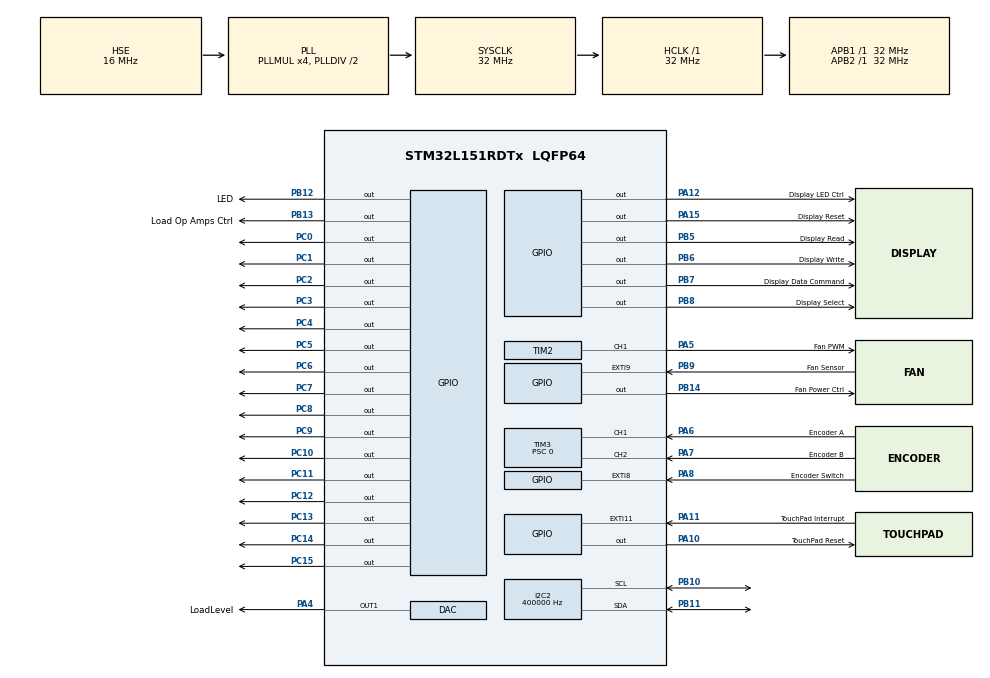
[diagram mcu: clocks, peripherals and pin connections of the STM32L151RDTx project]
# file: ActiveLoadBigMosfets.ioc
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DAC.DAC_OutputBuffer=DAC_OUTPUTBUFFER_DISABLE
I2C2.ClockSpeed=400000
I2C2.I2C_Mode=I2C_Fast
Mcu.Family=STM32L1
Mcu.Name=STM32L151RDTx
Mcu.Package=LQFP64
NVIC.EXTI15_10_IRQn=true\:0\:0\:false\:false\:true\:true\:true
NVIC.EXTI9_5_IRQn=true\:0\:0\:false\:false\:true\:true\:true
NVIC.PVD_IRQn=true\:0\:0\:false\:false\:true\:true\:true
NVIC.PriorityGroup=NVIC_PRIORITYGROUP_4
NVIC.TIM3_IRQn=true\:0\:0\:false\:false\:true\:true\:true
NVIC.TIM5_IRQn=true\:0\:0\:false\:false\:true\:true\:true
PA10.GPIO_Label=TouchPad Reset
PA10.PinState=GPIO_PIN_RESET
PA10.Signal=GPIO_Output
PA11.GPIO_Label=TouchPad Interrupt
PA11.GPIO_ModeDefaultEXTI=GPIO_MODE_IT_RISING_FALLING
PA11.GPIO_PuPd=GPIO_PULLDOWN
PA11.Signal=GPXTI11
PA12.GPIO_Label=Display LED Ctrl
PA12.GPIO_PuPd=GPIO_NOPULL
PA12.Signal=GPIO_Output
PA15.GPIO_Label=Display Reset
PA15.GPIO_Speed=GPIO_SPEED_FREQ_LOW
PA15.Signal=GPIO_Output
PA4.GPIO_Label=LoadLevel
PA4.Signal=COMP_DAC1_group
PA5.GPIO_Label=Fan PWM
PA5.GPIO_Speed=GPIO_SPEED_FREQ_VERY_HIGH
PA5.Signal=S_TIM2_CH1_ETR
PA6.GPIO_Label=Encoder A
PA6.GPIO_ModeDefaultPP=GPIO_MODE_AF_OD
PA6.GPIO_PuPd=GPIO_PULLUP
PA6.Signal=S_TIM3_CH1
PA7.GPIO_Label=Encoder B
PA7.GPIO_ModeDefaultPP=GPIO_MODE_AF_OD
PA7.GPIO_PuPd=GPIO_PULLUP
PA7.Signal=S_TIM3_CH2
PA8.GPIO_Label=Encoder Switch
PA8.GPIO_ModeDefaultEXTI=GPIO_MODE_IT_FALLING
PA8.GPIO_PuPd=GPIO_PULLUP
PA8.Signal=GPXTI8
PB10.Mode=I2C
PB10.Signal=I2C2_SCL
PB11.Mode=I2C
PB11.Signal=I2C2_SDA
PB12.GPIO_Label=LED
PB12.Signal=GPIO_Output
PB13.GPIO_Label=Load Op Amps Ctrl
PB13.Signal=GPIO_Output
PB14.GPIO_Label=Fan Power Ctrl
PB14.Signal=GPIO_Output
PB5.GPIO_Label=Display Read
PB5.Signal=GPIO_Output
PB6.GPIO_Label=Display Write
PB6.GPIO_Speed=GPIO_SPEED_FREQ_HIGH
PB6.Signal=GPIO_Output
PB7.GPIO_Label=Display Data Command
PB7.GPIO_Speed=GPIO_SPEED_FREQ_HIGH
PB7.Signal=GPIO_Output
PB8.GPIO_Label=Display Select
PB8.Signal=GPIO_Output
PB9.GPIO_Label=Fan Sensor
PB9.GPIO_ModeDefaultEXTI=GPIO_MODE_IT_FALLING
PB9.GPIO_PuPd=GPIO_PULLUP
PB9.Signal=GPXTI9
PC0.GPIO_Speed=GPIO_SPEED_FREQ_HIGH
PC0.Signal=GPIO_Output
PC1.GPIO_Speed=GPIO_SPEED_FREQ_HIGH
PC1.Signal=GPIO_Output
PC10.GPIO_Speed=GPIO_SPEED_FREQ_HIGH
PC10.Signal=GPIO_Output
PC11.GPIO_Speed=GPIO_SPEED_FREQ_HIGH
PC11.Signal=GPIO_Output
PC12.GPIO_Speed=GPIO_SPEED_FREQ_HIGH
PC12.Signal=GPIO_Output
PC13-WKUP2.GPIO_Speed=GPIO_SPEED_FREQ_HIGH
PC13-WKUP2.Signal=GPIO_Output
PC14-OSC32_IN.GPIO_Speed=GPIO_SPEED_FREQ_HIGH
PC14-OSC32_IN.Signal=GPIO_Output
PC15-OSC32_OUT.GPIO_Speed=GPIO_SPEED_FREQ_HIGH
PC15-OSC32_OUT.Signal=GPIO_Output
PC2.GPIO_Speed=GPIO_SPEED_FREQ_HIGH
PC2.Signal=GPIO_Output
PC3.GPIO_Speed=GPIO_SPEED_FREQ_HIGH
PC3.Signal=GPIO_Output
PC4.GPIO_Speed=GPIO_SPEED_FREQ_HIGH
PC4.Signal=GPIO_Output
PC5.GPIO_Speed=GPIO_SPEED_FREQ_HIGH
PC5.Signal=GPIO_Output
PC6.GPIO_Speed=GPIO_SPEED_FREQ_HIGH
PC6.Signal=GPIO_Output
PC7.GPIO_Speed=GPIO_SPEED_FREQ_HIGH
PC7.Signal=GPIO_Output
PC8.GPIO_Speed=GPIO_SPEED_FREQ_HIGH
PC8.Signal=GPIO_Output
PC9.GPIO_Speed=GPIO_SPEED_FREQ_HIGH
PC9.Signal=GPIO_Output
PH0-OSC_IN.Mode=HSE-External-Oscillator
PH0-OSC_IN.Signal=RCC_OSC_IN
PH1-OSC_OUT.Mode=HSE-External-Oscillator
PH1-OSC_OUT.Signal=RCC_OSC_OUT
ProjectManager.HeapSize=0x200
ProjectManager.StackSize=0x400
ProjectManager.TargetToolchain=STM32CubeIDE
RCC.48MHZClocksFreq_Value=32000000
RCC.AHBFreq_Value=32000000
RCC.APB1Freq_Value=32000000
RCC.APB1TimFreq_Value=32000000
RCC.APB2Freq_Value=32000000
RCC.APB2TimFreq_Value=32000000
RCC.HCLKFreq_Value=32000000
RCC.HSE_VALUE=16000000
RCC.HSI_VALUE=16000000
RCC.LSE_VALUE=32768
RCC.MSI_VALUE=2097000
RCC.PLLMUL=RCC_PLL_MUL4
RCC.PLLSourceVirtual=RCC_PLLSOURCE_HSE
RCC.RCC_RTC_Clock_Source_FROM_HSE=RCC_RTCCLKSOURCE_HSE_DIV16
RCC.RTCClockSelectionVirtual=RCC_RTCCLKSOURCE_HSE_DIV16
RCC.SYSCLKFreq_VALUE=32000000
RCC.SYSCLKSource=RCC_SYSCLKSOURCE_PLLCLK
RCC.VCOOutputFreq_Value=64000000
SH.COMP_DAC1_group.0=DAC_OUT1,DAC_OUT1
SH.S_TIM2_CH1_ETR.0=TIM2_CH1,PWM Generation1 CH1
SH.S_TIM3_CH1.0=TIM3_CH1,Encoder_Interface
SH.S_TIM3_CH2.0=TIM3_CH2,Encoder_Interface
SYS.Mode=PWR_PVD_MODE_IT_RISING_FALLING
SYS.PVDLevel=PWR_PVDLEVEL_6
TIM2.Channel-PWM\ Generation1\ CH1=TIM_CHANNEL_1
TIM2.Period=31
TIM2.Prescaler=40
TIM2.Pulse-PWM\ Generation1\ CH1=10
TIM3.ClockDivision=TIM_CLOCKDIVISION_DIV4
TIM3.CounterMode=TIM_COUNTERMODE_UP
TIM3.EncoderMode=TIM_ENCODERMODE_TI12
TIM3.IC1Filter=15
TIM3.IC1Prescaler=TIM_ICPSC_DIV1
TIM3.IC2Filter=15
TIM3.IC2Polarity=TIM_ICPOLARITY_FALLING
TIM3.IC2Prescaler=TIM_ICPSC_DIV1
TIM3.Period=100
TIM3.Prescaler=0
TIM4.Period=0xffff
TIM4.Prescaler=3199
TIM5.ClockDivision=TIM_CLOCKDIVISION_DIV1
TIM5.Period=19
TIM5.Prescaler=31999
VP_CRC_VS_CRC.Mode=CRC_Activate
VP_SYS_V_PVD_IN.Mode=Mode_PVD_Int
VP_TIM2_VS_ClockSourceINT.Mode=Internal
VP_TIM4_VS_ClockSourceINT.Mode=Internal
VP_TIM5_VS_ClockSourceINT.Mode=Internal
board=custom

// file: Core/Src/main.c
/* USER CODE BEGIN Header */
/**
  ******************************************************************************
  * @file           : main.c
  * @brief          : Main program body
  ******************************************************************************
  * @attention
  *
  * <h2><center>&copy; Copyright (c) 2020 STMicroelectronics.
  * All rights reserved.</center></h2>
  *
  * This software component is licensed by ST under BSD 3-Clause license,
  * the "License"; You may not use this file except in compliance with the
  * License. You may obtain a copy of the License at:
  *                        opensource.org/licenses/BSD-3-Clause
  *
  ******************************************************************************
  */
/* USER CODE END Header */

#include "main.h"

/* USER CODE BEGIN Includes */

#include "ActiveLoad.h"

/* USER CODE END Includes */

CRC_HandleTypeDef hcrc;

DAC_HandleTypeDef hdac;

I2C_HandleTypeDef hi2c2;

TIM_HandleTypeDef htim2;
TIM_HandleTypeDef htim3;
TIM_HandleTypeDef htim4;
TIM_HandleTypeDef htim5;

void SystemClock_Config(void);
static void MX_GPIO_Init(void);
static void MX_I2C2_Init(void);
static void MX_TIM3_Init(void);
static void MX_DAC_Init(void);
static void MX_TIM2_Init(void);
static void MX_CRC_Init(void);
static void MX_TIM5_Init(void);
static void MX_TIM4_Init(void);

int main(void)
{

  /* MCU Configuration--------------------------------------------------------*/

  /* Reset of all peripherals, Initializes the Flash interface and the Systick. */
  HAL_Init();

  /* Configure the system clock */
  SystemClock_Config();

  /* Initialize all configured peripherals */
  MX_GPIO_Init();
  MX_I2C2_Init();
  MX_TIM3_Init();
  MX_DAC_Init();
  MX_TIM2_Init();
  MX_CRC_Init();
  MX_TIM5_Init();
  MX_TIM4_Init();
  /* USER CODE BEGIN 2 */

  ActiveLoad_init();

  /* USER CODE END 2 */

  /* Infinite loop */
  while (1)
  {

    /* USER CODE BEGIN 3 */
	  ActiveLoad_loop();
  }
  /* USER CODE END 3 */
}

void SystemClock_Config(void)
{
  RCC_OscInitTypeDef RCC_OscInitStruct = {0};
  RCC_ClkInitTypeDef RCC_ClkInitStruct = {0};

  /** Configure the main internal regulator output voltage
  */
  __HAL_PWR_VOLTAGESCALING_CONFIG(PWR_REGULATOR_VOLTAGE_SCALE1);
  /** Initializes the CPU, AHB and APB busses clocks
  */
  RCC_OscInitStruct.OscillatorType = RCC_OSCILLATORTYPE_HSE;
  RCC_OscInitStruct.HSEState = RCC_HSE_ON;
  RCC_OscInitStruct.PLL.PLLState = RCC_PLL_ON;
  RCC_OscInitStruct.PLL.PLLSource = RCC_PLLSOURCE_HSE;
  RCC_OscInitStruct.PLL.PLLMUL = RCC_PLL_MUL4;
  RCC_OscInitStruct.PLL.PLLDIV = RCC_PLL_DIV2;
  if (HAL_RCC_OscConfig(&RCC_OscInitStruct) != HAL_OK)
  {
    Error_Handler();
  }
  /** Initializes the CPU, AHB and APB busses clocks
  */
  RCC_ClkInitStruct.ClockType = RCC_CLOCKTYPE_HCLK|RCC_CLOCKTYPE_SYSCLK
                              |RCC_CLOCKTYPE_PCLK1|RCC_CLOCKTYPE_PCLK2;
  RCC_ClkInitStruct.SYSCLKSource = RCC_SYSCLKSOURCE_PLLCLK;
  RCC_ClkInitStruct.AHBCLKDivider = RCC_SYSCLK_DIV1;
  RCC_ClkInitStruct.APB1CLKDivider = RCC_HCLK_DIV1;
  RCC_ClkInitStruct.APB2CLKDivider = RCC_HCLK_DIV1;

  if (HAL_RCC_ClockConfig(&RCC_ClkInitStruct, FLASH_LATENCY_1) != HAL_OK)
  {
    Error_Handler();
  }
}

static void MX_CRC_Init(void)
{

  hcrc.Instance = CRC;
  if (HAL_CRC_Init(&hcrc) != HAL_OK)
  {
    Error_Handler();
  }

}

static void MX_DAC_Init(void)
{

  DAC_ChannelConfTypeDef sConfig = {0};

  /** DAC Initialization
  */
  hdac.Instance = DAC;
  if (HAL_DAC_Init(&hdac) != HAL_OK)
  {
    Error_Handler();
  }
  /** DAC channel OUT1 config
  */
  sConfig.DAC_Trigger = DAC_TRIGGER_NONE;
  sConfig.DAC_OutputBuffer = DAC_OUTPUTBUFFER_DISABLE;
  if (HAL_DAC_ConfigChannel(&hdac, &sConfig, DAC_CHANNEL_1) != HAL_OK)
  {
    Error_Handler();
  }

}

static void MX_I2C2_Init(void)
{

  hi2c2.Instance = I2C2;
  hi2c2.Init.ClockSpeed = 400000;
  hi2c2.Init.DutyCycle = I2C_DUTYCYCLE_2;
  hi2c2.Init.OwnAddress1 = 0;
  hi2c2.Init.AddressingMode = I2C_ADDRESSINGMODE_7BIT;
  hi2c2.Init.DualAddressMode = I2C_DUALADDRESS_DISABLE;
  hi2c2.Init.OwnAddress2 = 0;
  hi2c2.Init.GeneralCallMode = I2C_GENERALCALL_DISABLE;
  hi2c2.Init.NoStretchMode = I2C_NOSTRETCH_DISABLE;
  if (HAL_I2C_Init(&hi2c2) != HAL_OK)
  {
    Error_Handler();
  }

}

static void MX_TIM2_Init(void)
{

  TIM_ClockConfigTypeDef sClockSourceConfig = {0};
  TIM_MasterConfigTypeDef sMasterConfig = {0};
  TIM_OC_InitTypeDef sConfigOC = {0};

  htim2.Instance = TIM2;
  htim2.Init.Prescaler = 40;
  htim2.Init.CounterMode = TIM_COUNTERMODE_UP;
  htim2.Init.Period = 31;
  htim2.Init.ClockDivision = TIM_CLOCKDIVISION_DIV1;
  htim2.Init.AutoReloadPreload = TIM_AUTORELOAD_PRELOAD_DISABLE;
  if (HAL_TIM_Base_Init(&htim2) != HAL_OK)
  {
    Error_Handler();
  }
  sClockSourceConfig.ClockSource = TIM_CLOCKSOURCE_INTERNAL;
  if (HAL_TIM_ConfigClockSource(&htim2, &sClockSourceConfig) != HAL_OK)
  {
    Error_Handler();
  }
  if (HAL_TIM_PWM_Init(&htim2) != HAL_OK)
  {
    Error_Handler();
  }
  sMasterConfig.MasterOutputTrigger = TIM_TRGO_RESET;
  sMasterConfig.MasterSlaveMode = TIM_MASTERSLAVEMODE_DISABLE;
  if (HAL_TIMEx_MasterConfigSynchronization(&htim2, &sMasterConfig) != HAL_OK)
  {
    Error_Handler();
  }
  sConfigOC.OCMode = TIM_OCMODE_PWM1;
  sConfigOC.Pulse = 10;
  sConfigOC.OCPolarity = TIM_OCPOLARITY_HIGH;
  sConfigOC.OCFastMode = TIM_OCFAST_DISABLE;
  if (HAL_TIM_PWM_ConfigChannel(&htim2, &sConfigOC, TIM_CHANNEL_1) != HAL_OK)
  {
    Error_Handler();
  }
  HAL_TIM_MspPostInit(&htim2);

}

static void MX_TIM3_Init(void)
{

  TIM_Encoder_InitTypeDef sConfig = {0};
  TIM_MasterConfigTypeDef sMasterConfig = {0};

  htim3.Instance = TIM3;
  htim3.Init.Prescaler = 0;
  htim3.Init.CounterMode = TIM_COUNTERMODE_UP;
  htim3.Init.Period = 100;
  htim3.Init.ClockDivision = TIM_CLOCKDIVISION_DIV4;
  htim3.Init.AutoReloadPreload = TIM_AUTORELOAD_PRELOAD_DISABLE;
  sConfig.EncoderMode = TIM_ENCODERMODE_TI12;
  sConfig.IC1Polarity = TIM_ICPOLARITY_RISING;
  sConfig.IC1Selection = TIM_ICSELECTION_DIRECTTI;
  sConfig.IC1Prescaler = TIM_ICPSC_DIV1;
  sConfig.IC1Filter = 15;
  sConfig.IC2Polarity = TIM_ICPOLARITY_FALLING;
  sConfig.IC2Selection = TIM_ICSELECTION_DIRECTTI;
  sConfig.IC2Prescaler = TIM_ICPSC_DIV1;
  sConfig.IC2Filter = 15;
  if (HAL_TIM_Encoder_Init(&htim3, &sConfig) != HAL_OK)
  {
    Error_Handler();
  }
  sMasterConfig.MasterOutputTrigger = TIM_TRGO_RESET;
  sMasterConfig.MasterSlaveMode = TIM_MASTERSLAVEMODE_DISABLE;
  if (HAL_TIMEx_MasterConfigSynchronization(&htim3, &sMasterConfig) != HAL_OK)
  {
    Error_Handler();
  }

}

static void MX_TIM4_Init(void)
{

  TIM_ClockConfigTypeDef sClockSourceConfig = {0};
  TIM_MasterConfigTypeDef sMasterConfig = {0};

  htim4.Instance = TIM4;
  htim4.Init.Prescaler = 3199;
  htim4.Init.CounterMode = TIM_COUNTERMODE_UP;
  htim4.Init.Period = 0xffff;
  htim4.Init.ClockDivision = TIM_CLOCKDIVISION_DIV1;
  htim4.Init.AutoReloadPreload = TIM_AUTORELOAD_PRELOAD_DISABLE;
  if (HAL_TIM_Base_Init(&htim4) != HAL_OK)
  {
    Error_Handler();
  }
  sClockSourceConfig.ClockSource = TIM_CLOCKSOURCE_INTERNAL;
  if (HAL_TIM_ConfigClockSource(&htim4, &sClockSourceConfig) != HAL_OK)
  {
    Error_Handler();
  }
  sMasterConfig.MasterOutputTrigger = TIM_TRGO_RESET;
  sMasterConfig.MasterSlaveMode = TIM_MASTERSLAVEMODE_DISABLE;
  if (HAL_TIMEx_MasterConfigSynchronization(&htim4, &sMasterConfig) != HAL_OK)
  {
    Error_Handler();
  }

}

static void MX_TIM5_Init(void)
{

  TIM_ClockConfigTypeDef sClockSourceConfig = {0};
  TIM_MasterConfigTypeDef sMasterConfig = {0};

  htim5.Instance = TIM5;
  htim5.Init.Prescaler = 31999;
  htim5.Init.CounterMode = TIM_COUNTERMODE_UP;
  htim5.Init.Period = 19;
  htim5.Init.ClockDivision = TIM_CLOCKDIVISION_DIV1;
  htim5.Init.AutoReloadPreload = TIM_AUTORELOAD_PRELOAD_DISABLE;
  if (HAL_TIM_Base_Init(&htim5) != HAL_OK)
  {
    Error_Handler();
  }
  sClockSourceConfig.ClockSource = TIM_CLOCKSOURCE_INTERNAL;
  if (HAL_TIM_ConfigClockSource(&htim5, &sClockSourceConfig) != HAL_OK)
  {
    Error_Handler();
  }
  sMasterConfig.MasterOutputTrigger = TIM_TRGO_RESET;
  sMasterConfig.MasterSlaveMode = TIM_MASTERSLAVEMODE_DISABLE;
  if (HAL_TIMEx_MasterConfigSynchronization(&htim5, &sMasterConfig) != HAL_OK)
  {
    Error_Handler();
  }

}

static void MX_GPIO_Init(void)
{
  GPIO_InitTypeDef GPIO_InitStruct = {0};

  /* GPIO Ports Clock Enable */
  __HAL_RCC_GPIOC_CLK_ENABLE();
  __HAL_RCC_GPIOH_CLK_ENABLE();
  __HAL_RCC_GPIOA_CLK_ENABLE();
  __HAL_RCC_GPIOB_CLK_ENABLE();

  /*Configure GPIO pin Output Level */
  HAL_GPIO_WritePin(GPIOC, GPIO_PIN_13|GPIO_PIN_14|GPIO_PIN_15|GPIO_PIN_0
                          |GPIO_PIN_1|GPIO_PIN_2|GPIO_PIN_3|GPIO_PIN_4
                          |GPIO_PIN_5|GPIO_PIN_6|GPIO_PIN_7|GPIO_PIN_8
                          |GPIO_PIN_9|GPIO_PIN_10|GPIO_PIN_11|GPIO_PIN_12, GPIO_PIN_RESET);

  /*Configure GPIO pin Output Level */
  HAL_GPIO_WritePin(GPIOB, LED_Pin|Load_Op_Amps_Ctrl_Pin|Fan_Power_Ctrl_Pin|Display_Read_Pin
                          |Display_Write_Pin|Display_Data_Command_Pin|Display_Select_Pin, GPIO_PIN_RESET);

  /*Configure GPIO pin Output Level */
  HAL_GPIO_WritePin(GPIOA, TouchPad_Reset_Pin|Display_LED_Ctrl_Pin|Display_Reset_Pin, GPIO_PIN_RESET);

  /*Configure GPIO pins : PC13 PC14 PC15 PC0
                           PC1 PC2 PC3 PC4
                           PC5 PC6 PC7 PC8
                           PC9 PC10 PC11 PC12 */
  GPIO_InitStruct.Pin = GPIO_PIN_13|GPIO_PIN_14|GPIO_PIN_15|GPIO_PIN_0
                          |GPIO_PIN_1|GPIO_PIN_2|GPIO_PIN_3|GPIO_PIN_4
                          |GPIO_PIN_5|GPIO_PIN_6|GPIO_PIN_7|GPIO_PIN_8
                          |GPIO_PIN_9|GPIO_PIN_10|GPIO_PIN_11|GPIO_PIN_12;
  GPIO_InitStruct.Mode = GPIO_MODE_OUTPUT_PP;
  GPIO_InitStruct.Pull = GPIO_NOPULL;
  GPIO_InitStruct.Speed = GPIO_SPEED_FREQ_HIGH;
  HAL_GPIO_Init(GPIOC, &GPIO_InitStruct);

  /*Configure GPIO pins : LED_Pin Load_Op_Amps_Ctrl_Pin Fan_Power_Ctrl_Pin Display_Read_Pin
                           Display_Select_Pin */
  GPIO_InitStruct.Pin = LED_Pin|Load_Op_Amps_Ctrl_Pin|Fan_Power_Ctrl_Pin|Display_Read_Pin
                          |Display_Select_Pin;
  GPIO_InitStruct.Mode = GPIO_MODE_OUTPUT_PP;
  GPIO_InitStruct.Pull = GPIO_NOPULL;
  GPIO_InitStruct.Speed = GPIO_SPEED_FREQ_LOW;
  HAL_GPIO_Init(GPIOB, &GPIO_InitStruct);

  /*Configure GPIO pin : Encoder_Switch_Pin */
  GPIO_InitStruct.Pin = Encoder_Switch_Pin;
  GPIO_InitStruct.Mode = GPIO_MODE_IT_FALLING;
  GPIO_InitStruct.Pull = GPIO_PULLUP;
  HAL_GPIO_Init(Encoder_Switch_GPIO_Port, &GPIO_InitStruct);

  /*Configure GPIO pins : TouchPad_Reset_Pin Display_LED_Ctrl_Pin Display_Reset_Pin */
  GPIO_InitStruct.Pin = TouchPad_Reset_Pin|Display_LED_Ctrl_Pin|Display_Reset_Pin;
  GPIO_InitStruct.Mode = GPIO_MODE_OUTPUT_PP;
  GPIO_InitStruct.Pull = GPIO_NOPULL;
  GPIO_InitStruct.Speed = GPIO_SPEED_FREQ_LOW;
  HAL_GPIO_Init(GPIOA, &GPIO_InitStruct);

  /*Configure GPIO pin : TouchPad_Interrupt_Pin */
  GPIO_InitStruct.Pin = TouchPad_Interrupt_Pin;
  GPIO_InitStruct.Mode = GPIO_MODE_IT_RISING_FALLING;
  GPIO_InitStruct.Pull = GPIO_PULLDOWN;
  HAL_GPIO_Init(TouchPad_Interrupt_GPIO_Port, &GPIO_InitStruct);

  /*Configure GPIO pins : Display_Write_Pin Display_Data_Command_Pin */
  GPIO_InitStruct.Pin = Display_Write_Pin|Display_Data_Command_Pin;
  GPIO_InitStruct.Mode = GPIO_MODE_OUTPUT_PP;
  GPIO_InitStruct.Pull = GPIO_NOPULL;
  GPIO_InitStruct.Speed = GPIO_SPEED_FREQ_HIGH;
  HAL_GPIO_Init(GPIOB, &GPIO_InitStruct);

  /*Configure GPIO pin : Fan_Sensor_Pin */
  GPIO_InitStruct.Pin = Fan_Sensor_Pin;
  GPIO_InitStruct.Mode = GPIO_MODE_IT_FALLING;
  GPIO_InitStruct.Pull = GPIO_PULLUP;
  HAL_GPIO_Init(Fan_Sensor_GPIO_Port, &GPIO_InitStruct);

  /* EXTI interrupt init*/
  HAL_NVIC_SetPriority(EXTI9_5_IRQn, 0, 0);
  HAL_NVIC_EnableIRQ(EXTI9_5_IRQn);

  HAL_NVIC_SetPriority(EXTI15_10_IRQn, 0, 0);
  HAL_NVIC_EnableIRQ(EXTI15_10_IRQn);

}

void Error_Handler(void)
{
}

/************************ (C) COPYRIGHT STMicroelectronics *****END OF FILE****/
